# nrf54l09_enga_flpr register map
Vendor: Nordic Semiconductor; Series: nrf54l; File version: 1
Registers are 32-bit, read-write, reset 0x0 unless marked. A register's access mark holds for its fields unless they carry their own. Offsets are from the block's base; [hi:lo] are bit positions; lines under a group give offsets from that group; {n}, {i} and the like mark numbered series; 'fields as' and 'values as' point back to an identical list.

## GLOBAL_POWER_NS — Power control 0
Base 0x4010E000; alternate view of GLOBAL_CLOCK_NS
Same registers: GLOBAL_POWER_S 0x5010E000 (alternate view of GLOBAL_CLOCK_S)
0x30 TASKS_CONSTLAT wo — Enable Constant Latency mode
  [0] TASKS_CONSTLAT
    1=Trigger task
0x34 TASKS_LOWPWR wo — Enable Low-power mode (variable latency)
  [0] TASKS_LOWPWR
    1=Trigger task
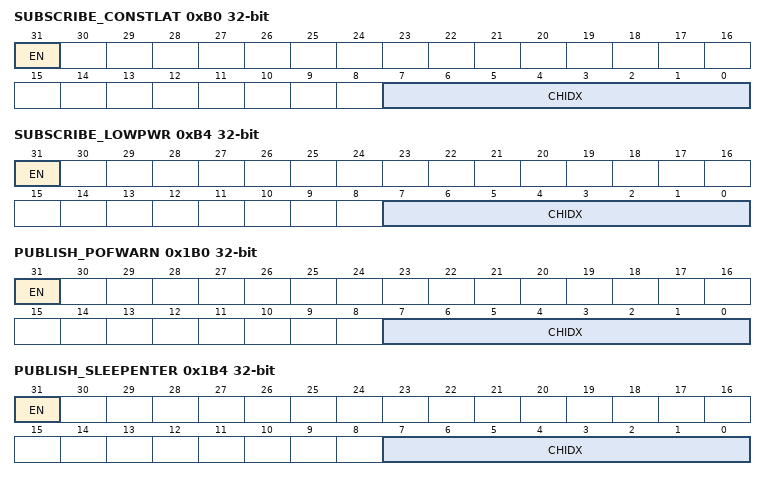
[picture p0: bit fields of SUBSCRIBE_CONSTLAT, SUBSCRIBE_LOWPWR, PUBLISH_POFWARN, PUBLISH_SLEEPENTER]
0xB0 SUBSCRIBE_CONSTLAT — Subscribe configuration for task CONSTLAT
  [31] EN
    0=Disabled (Disable subscription); 1=Enabled (Enable subscription)
  [7:0] CHIDX — DPPI channel that task CONSTLAT will subscribe to
0xB4 SUBSCRIBE_LOWPWR — Subscribe configuration for task LOWPWR
  [31] EN
    values as SUBSCRIBE_CONSTLAT.EN
  [7:0] CHIDX — DPPI channel that task LOWPWR will subscribe to
0x130 EVENTS_POFWARN — Power failure warning
  [0] EVENTS_POFWARN
    0=NotGenerated (Event not generated); 1=Generated (Event generated)
0x134 EVENTS_SLEEPENTER — CPU entered WFI/WFE sleep
  [0] EVENTS_SLEEPENTER
    values as EVENTS_POFWARN.EVENTS_POFWARN
0x138 EVENTS_SLEEPEXIT — CPU exited WFI/WFE sleep
  [0] EVENTS_SLEEPEXIT
    values as EVENTS_POFWARN.EVENTS_POFWARN
0x1B0 PUBLISH_POFWARN — Publish configuration for event POFWARN
  [31] EN
    0=Disabled (Disable publishing); 1=Enabled (Enable publishing)
  [7:0] CHIDX — DPPI channel that event POFWARN will publish to
0x1B4 PUBLISH_SLEEPENTER — Publish configuration for event SLEEPENTER
  [31] EN
    values as PUBLISH_POFWARN.EN
  [7:0] CHIDX — DPPI channel that event SLEEPENTER will publish to
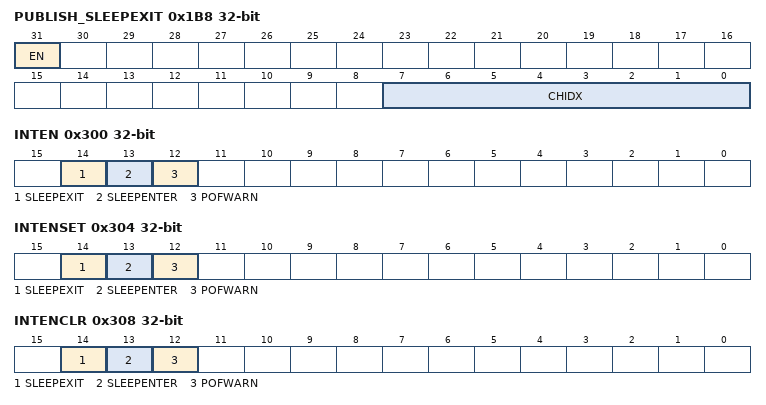
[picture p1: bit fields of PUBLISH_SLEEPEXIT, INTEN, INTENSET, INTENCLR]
0x1B8 PUBLISH_SLEEPEXIT — Publish configuration for event SLEEPEXIT
  [31] EN
    values as PUBLISH_POFWARN.EN
  [7:0] CHIDX — DPPI channel that event SLEEPEXIT will publish to
0x300 INTEN — Enable or disable interrupt
  [all] fields
    0=Disabled; 1=Enabled
  [14] SLEEPEXIT — Enable or disable interrupt for event SLEEPEXIT
  [13] SLEEPENTER — Enable or disable interrupt for event SLEEPENTER
  [12] POFWARN — Enable or disable interrupt for event POFWARN
0x304 INTENSET — Enable interrupt
  [all] fields
    on read: 0=Disabled (Read: Disabled); 1=Enabled (Read: Enabled) | on write: 1=Set (Enable)
  [14] SLEEPEXIT — Write '1' to enable interrupt for event SLEEPEXIT
  [13] SLEEPENTER — Write '1' to enable interrupt for event SLEEPENTER
  [12] POFWARN — Write '1' to enable interrupt for event POFWARN
0x308 INTENCLR — Disable interrupt
  [all] fields
    on read: 0=Disabled (Read: Disabled); 1=Enabled (Read: Enabled) | on write: 1=Clear (Disable)
  [14] SLEEPEXIT — Write '1' to disable interrupt for event SLEEPEXIT
  [13] SLEEPENTER — Write '1' to disable interrupt for event SLEEPENTER
  [12] POFWARN — Write '1' to disable interrupt for event POFWARN
{0x500+4i} GPREGRET[{i}] (i=0..1) — Description collection: General purpose retention register
  [7:0] GPREGRET — General purpose retention register
0x510 CONSTLATSTAT ro — Status of constant latency
  [0] STATUS
    0=Disable (Constant latency disabled); 1=Enable (Constant latency enabled)

## GLOBAL_RESET_NS — Reset control 0
Base 0x4010E000; alternate view of GLOBAL_CLOCK_NS
Same registers: GLOBAL_RESET_S 0x5010E000 (alternate view of GLOBAL_CLOCK_S)
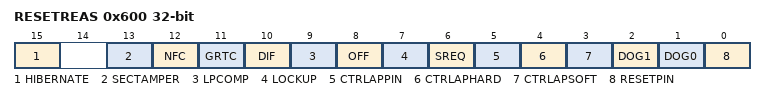
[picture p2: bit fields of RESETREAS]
0x600 RESETREAS — Reset reason
  [all] fields
    0=NotDetected; 1=Detected
  [15] HIBERNATE — Reset after wakeup from Hibernate mode
  [13] SECTAMPER — Reset due to illegal tampering of the device
  [12] NFC — Reset after wakeup from System OFF mode due to NFC field being detected
  [11] GRTC — Reset due to wakeup from GRTC
  [10] DIF — Reset triggered by Debug Interface
  [9] LPCOMP — Reset due to wakeup from System OFF mode when wakeup is triggered by ANADETECT signal from LPCOMP
  [8] OFF — Reset due to wakeup from System OFF mode when wakeup is triggered by DETECT signal from GPIO
  [7] LOCKUP — Reset from CPU lockup detected
  [6] SREQ — Reset from soft reset detected
  [5] CTRLAPPIN — Reset due to CTRL-AP pin reset
  [4] CTRLAPHARD — Reset due to CTRL-AP hard reset
  [3] CTRLAPSOFT — Soft reset from CTRL-AP detected
  [2] DOG1 — Reset from watchdog timer 1 detected
  [1] DOG0 — Reset from watchdog timer 0 detected
  [0] RESETPIN — Reset from pin reset detected

## GLOBAL_OSCILLATORS_NS — Oscillator control 0
Base 0x40120000
Same registers: GLOBAL_OSCILLATORS_S 0x50120000
0x700 XOSC32M group — 32 MHz oscillator control
  0x14 CONFIG group — Unspecified
    0x08 INTCAP reset 0x20 — Crystal load capacitor as seen by the crystal across its terminals, including pin capacitance but excluding PCB stray capacitance.
      [5:0] VAL — Crystal load capacitor value
0x800 PLL group — Oscillator control
  0x00 FREQ reset 0x3 — Set speed of MCU power domain, including CPU
    [1:0] FREQ — Select CPU speed
      1=CK128M (128 MHz); 3=CK64M (64 MHz)
  0x04 CURRENTFREQ ro reset 0x3 — Current speed of MCU power domain, including CPU
    [1:0] CURRENTFREQ — Active CPU speed
      1=CK128M (128 MHz); 3=CK64M (64 MHz)
0x900 XOSC32KI group — 32.768 kHz oscillator control
  0x04 INTCAP reset 0x17 — Programmable capacitance of XL1 and XL2
    [4:0] VAL — Crystal load capacitor as seen by the crystal across its terminals, including pin capacitance but excluding PCB stray capacitance.

## GLOBAL_REGULATORS_NS — Voltage regulators 0
Base 0x40120000; alternate view of GLOBAL_OSCILLATORS_NS
Same registers: GLOBAL_REGULATORS_S 0x50120000 (alternate view of GLOBAL_OSCILLATORS_S)
0x400 HIBERNATOR group — Hibernator interface
  0x00 SYSTEMHIBERNATE wo — Enter System hibernation mode for extreme low power consumption
    [0] SYSTEMHIBERNATE — Enter hibernation mode
      1=Enter hibernation mode
  0x04 GPIORETENTIONRELEASE — Release GPIO retention on wake up from hibernation mode.
    [0] GPIORETENTIONRELEASE — Release GPIO retention
      0=NoRelease (Do not release retention); 1=Release retention
  0x08 GPIORETENTIONSTATUS ro — Read out if GPIO retention is active.
    [0] GPIORETENTIONSTATUS
      0=NotActive (GPIO retention is not active.); 1=Active (GPIO retention is active.)
0x500 SYSTEMOFF wo
  [0] SYSTEMOFF — Enable System OFF mode
    1=Enter (Enable System OFF mode)
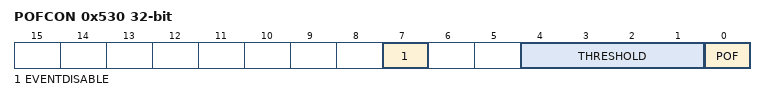
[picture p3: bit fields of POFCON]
0x530 POFCON — Power-fail comparator configuration
  [7] EVENTDISABLE — Disable the POFWARN power-fail warning event
    0=Enabled (POFWARN event is generated); 1=Disabled (POFWARN event is not generated)
  [4:1] THRESHOLD — Power-fail comparator threshold setting
    0=V17 (Set threshold to 1.7 V); 1=V18 (Set threshold to 1.8 V); 2=V19 (Set threshold to 1.9 V); 3=V20 (Set threshold to 2.0 V); 4=V21 (Set threshold to 2.1 V); 5=V22 (Set threshold to 2.2 V); 6=V23 (Set threshold to 2.3 V); 7=V24 (Set threshold to 2.4 V); 8=V25 (Set threshold to 2.5 V); 9=V26 (Set threshold to 2.6 V); 10=V27 (Set threshold to 2.7 V); 11=V28 (Set threshold to 2.8 V)
  [0] POF — Enable or disable power-fail comparator
    0=Disabled; 1=Enabled
0x534 POFSTAT ro — Power-fail comparator status register
  [0] COMPARATOR — Power-fail comparator status
    0=Above (Voltage detected above VPOF threshold); 1=Below (Voltage detected below VPOF threshold)
0x600 VREGMAIN group — Register interface for main voltage regulator.
  0x00 DCDCEN — Enable DC/DC converter for better power efficiency
    [0] VAL — Enable DC/DC buck converter
      0=Disable DC/DC converter and use LDO; 1=Enable DC/DC converter
  0x04 INDUCTORDET ro — VREGMAIN inductor detection
    [0] DETECTED
      0=InductorNotDetected (VREGMAIN inductor not detected); 1=InductorDetected (VREGMAIN inductor detected)

## Notices in the file
Copyright (c) 2010 - 2025, Nordic Semiconductor ASA All rights reserved.
SPDX-License-Identifier: BSD-3-Clause
Redistribution and use in source and binary forms, with or without
modification, are permitted provided that the following conditions are met:
1. Redistributions of source code must retain the above copyright notice, this
list of conditions and the following disclaimer.
2. Redistributions in binary form must reproduce the above copyright
notice, this list of conditions and the following disclaimer in the
documentation and/or other materials provided with the distribution.
3. Neither the name of Nordic Semiconductor ASA nor the names of its
contributors may be used to endorse or promote products derived from this
software without specific prior written permission.
THIS SOFTWARE IS PROVIDED BY THE COPYRIGHT HOLDERS AND CONTRIBUTORS "AS IS"
AND ANY EXPRESS OR IMPLIED WARRANTIES, INCLUDING, BUT NOT LIMITED TO, THE
IMPLIED WARRANTIES OF MERCHANTABILITY, AND FITNESS FOR A PARTICULAR PURPOSE
ARE DISCLAIMED. IN NO EVENT SHALL NORDIC SEMICONDUCTOR ASA OR CONTRIBUTORS BE
LIABLE FOR ANY DIRECT, INDIRECT, INCIDENTAL, SPECIAL, EXEMPLARY, OR
CONSEQUENTIAL DAMAGES (INCLUDING, BUT NOT LIMITED TO, PROCUREMENT OF
SUBSTITUTE GOODS OR SERVICES; LOSS OF USE, DATA, OR PROFITS; OR BUSINESS
INTERRUPTION) HOWEVER CAUSED AND ON ANY THEORY OF LIABILITY, WHETHER IN
CONTRACT, STRICT LIABILITY, OR TORT (INCLUDING NEGLIGENCE OR OTHERWISE)
ARISING IN ANY WAY OUT OF THE USE OF THIS SOFTWARE, EVEN IF ADVISED OF THE
POSSIBILITY OF SUCH DAMAGE.
